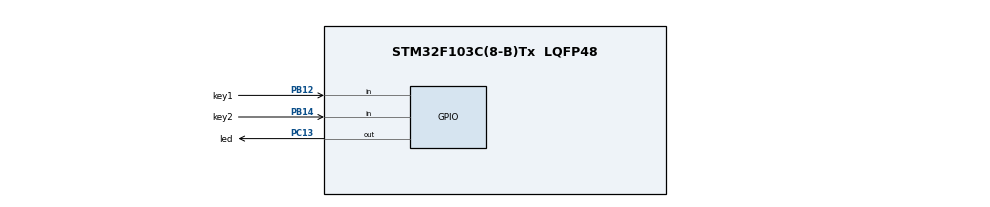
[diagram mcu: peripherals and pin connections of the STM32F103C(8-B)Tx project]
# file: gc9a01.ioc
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Mcu.Family=STM32F1
Mcu.Name=STM32F103C(8-B)Tx
Mcu.Package=LQFP48
NVIC.PriorityGroup=NVIC_PRIORITYGROUP_4
PB12.GPIO_Label=key1
PB12.GPIO_PuPd=GPIO_PULLUP
PB12.Signal=GPIO_Input
PB14.GPIO_Label=key2
PB14.GPIO_PuPd=GPIO_PULLUP
PB14.Signal=GPIO_Input
PC13-TAMPER-RTC.GPIO_Label=led
PC13-TAMPER-RTC.GPIO_PuPd=GPIO_PULLUP
PC13-TAMPER-RTC.Signal=GPIO_Output
PD0-OSC_IN.Mode=HSE-External-Oscillator
PD0-OSC_IN.Signal=RCC_OSC_IN
PD1-OSC_OUT.Mode=HSE-External-Oscillator
PD1-OSC_OUT.Signal=RCC_OSC_OUT
ProjectManager.HeapSize=0x200
ProjectManager.StackSize=0x400
ProjectManager.TargetToolchain=CMake
RCC.AHBFreq_Value=72000000
RCC.APB1CLKDivider=RCC_HCLK_DIV2
RCC.APB1Freq_Value=36000000
RCC.APB1TimFreq_Value=72000000
RCC.APB2Freq_Value=72000000
RCC.APB2TimFreq_Value=72000000
RCC.HCLKFreq_Value=72000000
RCC.PLLMUL=RCC_PLL_MUL9
RCC.PLLSourceVirtual=RCC_PLLSOURCE_HSE
RCC.SYSCLKFreq_VALUE=72000000
RCC.SYSCLKSource=RCC_SYSCLKSOURCE_PLLCLK
RCC.USBFreq_Value=72000000
VP_SYS_VS_ND.Mode=No_Debug
board=custom

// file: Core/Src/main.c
/* USER CODE BEGIN Header */
/**
  ******************************************************************************
  * @file           : main.c
  * @brief          : Main program body
  ******************************************************************************
  * @attention
  *
  * Copyright (c) 2026 STMicroelectronics.
  * All rights reserved.
  *
  * This software is licensed under terms that can be found in the LICENSE file
  * in the root directory of this software component.
  * If no LICENSE file comes with this software, it is provided AS-IS.
  *
  ******************************************************************************
  */
/* USER CODE END Header */
#include "main.h"
#include "gpio.h"

/* USER CODE BEGIN Includes */
#include "bsp_includes.h"
/* USER CODE END Includes */

/* USER CODE BEGIN PV */
volatile LCD_Result g_tft_init_result = LCD_OK;
/* USER CODE END PV */

void SystemClock_Config(void);

int main(void)
{

  /* MCU Configuration--------------------------------------------------------*/

  /* Reset of all peripherals, Initializes the Flash interface and the Systick. */
  LL_APB2_GRP1_EnableClock(LL_APB2_GRP1_PERIPH_AFIO);
  LL_APB1_GRP1_EnableClock(LL_APB1_GRP1_PERIPH_PWR);

  /* System interrupt init*/
  NVIC_SetPriorityGrouping(NVIC_PRIORITYGROUP_4);

  /* SysTick_IRQn interrupt configuration */
  NVIC_SetPriority(SysTick_IRQn, NVIC_EncodePriority(NVIC_GetPriorityGrouping(),15, 0));

  /* CubeMX 默认的 DisableRemap_SWJ 会同时关闭 JTAG-DP 与 SW-DP，
     程序一旦运行 SWD 调试/下载口即断开。PB10/PB11 不属于 SWJ 引脚，
     改为 NOJTAG 保留 SW-DP，二者无冲突。 */
  /** NOJTAG: JTAG-DP Disabled and SW-DP Enabled
  */
  LL_GPIO_AF_Remap_SWJ_NOJTAG();

  /* Configure the system clock */
  SystemClock_Config();

  /* Initialize all configured peripherals */
  MX_GPIO_Init();
  /* USER CODE BEGIN 2 */

  /* 1. 统一时间基准：SysTick 1ms 心跳 + DWT 微秒计时 */
  Timebase_Init();

#if defined(CONFIG_TFT_ONLY) && (CONFIG_TFT_ONLY != 0)
  /* TFT_ONLY 硬件最小诊断模式：
   * 仅初始化 SPI1 和 GC9A01，不运行 Flash 测试、TIM2 压力测试和复杂 UI。
   * 初始使用 1.125 MHz 轮询模式，依次填充黑、红、绿、蓝、白 5 种纯色。
   */
  AppTFT_DiagRun(1125000U, 0U);

  /* USER CODE END 2 */

  /* Infinite loop */
  while (1)
  {

    /* USER CODE BEGIN 3 */
    AppTFT_DiagLoop();
  }
  /* USER CODE END 3 */
#elif defined(CONFIG_HIL_TESTS) && (CONFIG_HIL_TESTS != 0)
  /* 目标 HIL 自动化回归测试模式：
   * 运行 SPI 契约测试、TIM2 中断抢占压力测试与 Flash 读写一致性校验。
   */
  AppHIL_Run();

  /* USER CODE END 2 */

  /* Infinite loop */
  while (1)
  {

    /* USER CODE BEGIN 3 */
    AppHIL_Task();
  }
  /* USER CODE END 3 */
#else
  /* 正式应用交互式 Demo 模式：
   * 1. 初始化 KEY1 (PB12) 与 LED (PC13)
   * 2. 初始化 GC9A01 TFT (SPI1, 18MHz DMA)
   * 3. 初始化 W25Q128 Flash (SPI2, 9MHz DMA)
   * 4. 启动交互式 Demo 主菜单
   */
  KEY_Init();
  g_tft_init_result = GC9A01_PortInit();
  W25QXX_PortInit();

  if (g_tft_init_result == LCD_OK) {
    AppDemo_Init();
  }

  /* USER CODE END 2 */

  /* Infinite loop */
  while (1)
  {

    /* USER CODE BEGIN 3 */
    AppDemo_Run();
  }
  /* USER CODE END 3 */
#endif
}

void SystemClock_Config(void)
{
  LL_FLASH_SetLatency(LL_FLASH_LATENCY_2);
  while(LL_FLASH_GetLatency()!= LL_FLASH_LATENCY_2)
  {
  }
  LL_RCC_HSE_Enable();

   /* Wait till HSE is ready */
  while(LL_RCC_HSE_IsReady() != 1)
  {

  }
  LL_RCC_PLL_ConfigDomain_SYS(LL_RCC_PLLSOURCE_HSE_DIV_1, LL_RCC_PLL_MUL_9);
  LL_RCC_PLL_Enable();

   /* Wait till PLL is ready */
  while(LL_RCC_PLL_IsReady() != 1)
  {

  }
  LL_RCC_SetAHBPrescaler(LL_RCC_SYSCLK_DIV_1);
  LL_RCC_SetAPB1Prescaler(LL_RCC_APB1_DIV_2);
  LL_RCC_SetAPB2Prescaler(LL_RCC_APB2_DIV_1);
  LL_RCC_SetSysClkSource(LL_RCC_SYS_CLKSOURCE_PLL);

   /* Wait till System clock is ready */
  while(LL_RCC_GetSysClkSource() != LL_RCC_SYS_CLKSOURCE_STATUS_PLL)
  {

  }
  LL_Init1msTick(72000000);
  LL_SetSystemCoreClock(72000000);
}

void Error_Handler(void)
{
  __disable_irq();
  while (1)
  {
  }
}
